# SN32F780 register map
Vendor: SONiX Technology Co., Ltd.; Series: SN32F780; File version: 0.75
CPU: CM0 r0p0, little endian, no MPU, no FPU, 2 interrupt priority bits
Registers are 32-bit, read-write, reset 0x0 unless marked. A register's access mark holds for its fields unless they carry their own. Offsets are from the block's base; [hi:lo] are bit positions; {n}, {i} and the like mark numbered series; 'fields as' and 'values as' point back to an identical list.

## SN_CT16B0 — 16-bit Timer 0 with Capture function
Base 0x40000000
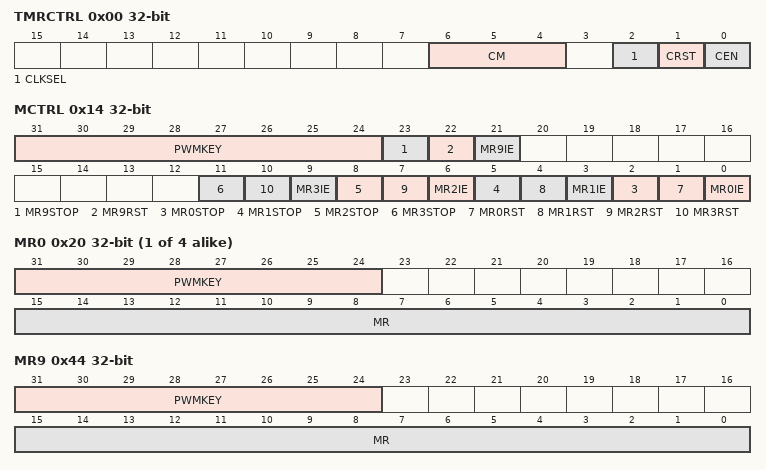
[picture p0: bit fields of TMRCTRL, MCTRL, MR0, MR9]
0x00 TMRCTRL — Offset:0x00 CT16Bn Timer Control Register
  [6:4] CM — Counting mode selection
    0=Up-counting mode (Edge-aligned Up-counting mode); 1=Down-counting mode (Edge-aligned Down-counting mode); 2=Center-aligned counting mode 1 (The match interrupt flag is set during the down-counting period); 4=Center-aligned counting mode 2 (The match interrupt flag is set during the up-counting period); 6=Center-aligned counting mode 3 (The match interrupt flag is set during both up-counting and down-counting period)
  [2] CLKSEL — PCLK source
    0=HCLK (CT16Bn PCLK source=HCLK); 1=PLL_VCO (CT16Bn PCLK source=PLL_VCO)
  [1] CRST — Counter Reset
    0=Disable Counter; 1=Reset Counter (Timer Counter and the Prescale Counter are synchronously reset on the next positive edge of PCLK)
  [0] CEN — Counter enable
    0=Disable counter; 1=Enable Timer Counter and Prescale Counter for counting
0x04 TC — Offset:0x04 CT16Bn Timer Counter Register
  [15:0] TC — Timer Counter
0x08 PRE — Offset:0x08 CT16Bn Prescale Register
  [7:0] PRE — Prescaler
0x0C PC — Offset:0x0C CT16Bn Prescale Counter Register
  [7:0] PC — Prescaler Counter
0x10 CNTCTRL — Offset:0x10 CT16Bn Counter Control Register
  [1:0] CTM — Counter/Timer Mode
    0=Timer Mode: every rising PCLK edge; 1=Counter Mode 1 (TC is incremented on rising edges on the CAP0 input selected by CIS bits.); 2=Counter Mode 2 (TC is incremented on falling edges on the CAP0 input selected by CIS bits.); 3=Counter Mode 3 (TC is incremented on both edges on the CAP0 input selected by CIS bits.)
0x14 MCTRL — Offset:0x14 CT16Bn Match Control Register
  [31:24] PWMKEY wo — PWM register key.
  [23] MR9STOP — Stop TC and PC and clear CEN bit when MR9 matches TC
    0=Disable; 1=Enable (Stop TC and PC and clear CEN bit when MR9 matches TC)
  [22] MR9RST — Enable reset TC when MR9 matches TC
    0=Disable; 1=Enable (Reset TC when MR9 matches TC)
  [21] MR9IE — Enable generating an interrupt based on CM[2:0] when MR9 matches the value in the TC
    0=Disable; 1=Enable (Generating an interrupt when MR9 matches TC)
  [3n+2] MR{n}STOP (n=0..3) — Stop TC and PC and clear CEN bit when MR{n} matches TC
    0=Disable; 1=Enable (Stop TC and PC and clear CEN bit when MR{n} matches TC)
  [3n+1] MR{n}RST (n=0..3) — Enable reset TC when MR{n} matches TC
    0=Disable; 1=Enable (Reset TC when MR{n} matches TC)
  [3n] MR{n}IE (n=0..3) — Enable generating an interrupt when MR{n} matches TC
    0=Disable; 1=Enable (Generating an interrupt when MR{n} matches TC)
{0x20+4i} MR{i} (i=0..3) — Offset:{0x20+4i} CT16Bn MR{i} Register
  [31:24] PWMKEY wo — PWM register key
  [15:0] MR — Timer counter match value
0x44 MR9 — Offset:0x44 CT16Bn MR9 Register
  fields as MR0
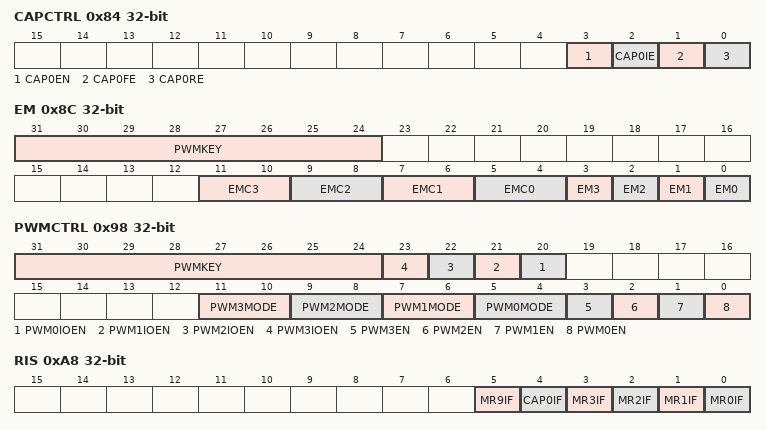
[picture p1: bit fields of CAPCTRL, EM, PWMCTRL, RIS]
0x84 CAPCTRL — Offset:0x84 CT16Bn Capture Control Register
  [3] CAP0EN — CAP0 function enable
    0=Disable; 1=Enable CAP0 function for external Capture pin
  [2] CAP0IE — Interrupt on CT16Bn_CAP0 event
    0=Disable; 1=Enable (A CAP0 load due to a CT16Bn_CAP0 event will generate an interrupt.)
  [1] CAP0FE — Capture/Reset on CT16Bn_CAP0 signal falling edge
    0=Disable; 1=Enable (A sequence of 1 then 0 on CT16Bn_CAP0 will cause CAP0 to be loaded with the contents of TC.)
  [0] CAP0RE — Capture/Reset on CT16Bn_CAP0 signal rising edge
    0=Disable; 1=Enable (A sequence of 0 then 1 on CT16Bn_CAP0 will cause CAP0 to be loaded with the contents of TC.)
0x88 CAP0 ro — Offset:0x88 CT16Bn CAP0 Register
  [15:0] CAP0 — Timer counter capture value
0x8C EM — Offset:0x8C CT16Bn External Match Register
  [31:24] PWMKEY wo — PWM register key.
  [2n+5:2n+4] EMC{n} (n=0..3) — CT16Bn_PWM{n} functionality when MR{n}=TC
    0=Do Nothing; 1=Low (CT16Bn_PWM{n} pin is LOW); 2=High (CT16Bn_PWM{n} pin is HIGH); 3=Toggle CT16Bn_PWM{n} pin
  [n] EM{n} (n=0..3) — When the TC doesn't match MR{n} and EMC{n} is not 0, this bit will drive the state of CT16Bn_PWM{n} output.
0x98 PWMCTRL — Offset:0x98 CT16Bn PWM Control Register
  [31:24] PWMKEY wo — PWM register key.
  [n+20] PWM{n}IOEN (n=0..3) — CT16Bn_PWM{n}/GPIO selection
    0=Disable (CT16Bn_PWM{n} pin is act as GPIO); 1=Enable (CT16Bn_PWM{n} pin act as match output, and output depends on PWM{n}EN bit)
  [2n+5:2n+4] PWM{n}MODE (n=0..3) — PWM{n} output mode
    0=PWM mode 1 (During up-counting, PWM{n} is 0 when TC is less than MR{n}.); 1=PWM mode 2 (During up-counting, PWM{n} is 1 when TC is less than MR{n}.); 2=Force 0 (PWM{n} is forced to 0); 3=Force 1 (PWM{n} is forced to 1)
  [3] PWM3EN — PWM2 enable
    0=Disable (CT16Bn_PWM3 is controlled by EMC3); 1=Enable PWM mode for CT16Bn_PWM3
  [2] PWM2EN — PWM2 enable
    0=Disable (CT16Bn_PWM2 is controlled by EMC2); 1=Enable PWM mode for CT16Bn_PWM2
  [1] PWM1EN — PWM1 enable
    0=Disable (CT16Bn_PWM1 is controlled by EMC1); 1=Enable PWM mode for CT16Bn_PWM1
  [0] PWM0EN — PWM0 enable
    0=Disable (CT16Bn_PWM0 is controlled by EMC0); 1=Enable PWM mode for CT16Bn_PWM0
0xA8 RIS ro — Offset:0xA8 CT16Bn Raw Interrupt Status Register
  [5] MR9IF — Match channel 9 interrupt flag
    0=No (No interrupt on match channel 9); 1=Met interrupt requirements (Interrupt requirements met on match channel 9)
  [4] CAP0IF — Capture channel 0 interrupt flag
    0=No (No interrupt on CAP0); 1=Met interrupt requirements (Interrupt requirements met on CAP0)
  [3] MR3IF — Match channel 3 interrupt flag
    0=No (No interrupt on match channel 3); 1=Met interrupt requirements (Interrupt requirements met on match channel 3)
  [2] MR2IF — Match channel 2 interrupt flag
    0=No (No interrupt on match channel 2); 1=Met interrupt requirements (Interrupt requirements met on match channel 2)
  [1] MR1IF — Match channel 1 interrupt flag
    0=No (No interrupt on match channel 1); 1=Met interrupt requirements (Interrupt requirements met on match channel 1)
  [0] MR0IF — Match channel 0 interrupt flag
    0=No interrupt on match channel 0; 1=Met interrupt requirements (Interrupt requirements met on match channel 0)
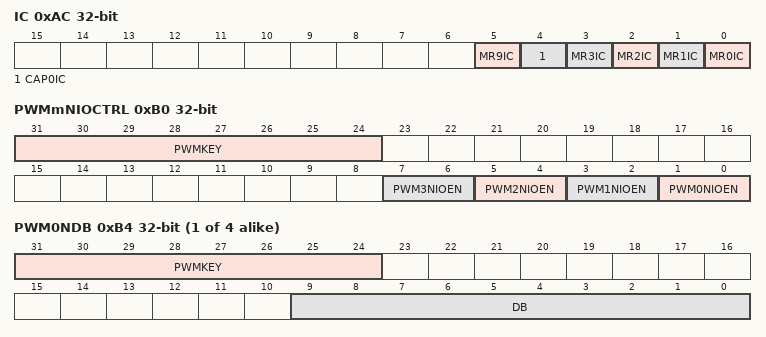
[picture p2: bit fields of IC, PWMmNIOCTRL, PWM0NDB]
0xAC IC wo — Offset:0xAC CT16Bn Interrupt Clear Register
  [5] MR9IC — MR9IF clear bit
    0=No effect; 1=Clear MR9IF
  [4] CAP0IC — CAP0IF clear bit
    0=No effect; 1=Clear CAP0IF
  [n] MR{n}IC (n=0..3) — MR{n}IF clear bit
    0=No effect; 1=Clear MR{n}IF
0xB0 PWMmNIOCTRL — Offset:0xB0 CT16Bn PWMmN IO Control register
  [31:24] PWMKEY wo — PWM register key.
  [7:6] PWM3NIOEN — CT16Bn_PWM3N/GPIO selection bit
    0=CT16Bn_PWM3N pin is act as GPIO; 1=CT16Bn_PWM3N pin outputs the inverse signal with dead-band of CT16Bn_PWM3, but same High signal during dead-band period; 2=CT16Bn_PWM3N pin outputs the inverse signal with dead-band of CT16Bn_PWM3, but same Low signal during dead-band period; 3=CT16Bn_PWM3N pin outputs the same signal with dead-band of CT16Bn_PWM3
  [5:4] PWM2NIOEN — CT16Bn_PWM0N/GPIO selection bit
    0=CT16Bn_PWM2N pin is act as GPIO; 1=CT16Bn_PWM2N pin outputs the inverse signal with dead-band of CT16Bn_PWM0, but same High signal during dead-band period; 2=CT16Bn_PWM2N pin outputs the inverse signal with dead-band of CT16Bn_PWM0, but same Low signal during dead-band period; 3=CT16Bn_PWM2N pin outputs the same signal with dead-band of CT16Bn_PWM0
  [3:2] PWM1NIOEN — CT16Bn_PWM0N/GPIO selection bit
    0=CT16Bn_PWM1N pin is act as GPIO; 1=CT16Bn_PWM1N pin outputs the inverse signal with dead-band of CT16Bn_PWM0, but same High signal during dead-band period; 2=CT16Bn_PWM1N pin outputs the inverse signal with dead-band of CT16Bn_PWM0, but same Low signal during dead-band period; 3=CT16Bn_PWM1N pin outputs the same signal with dead-band of CT16Bn_PWM0
  [1:0] PWM0NIOEN — CT16Bn_PWM0N/GPIO selection bit
    0=CT16Bn_PWM0N pin is act as GPIO; 1=CT16Bn_PWM0N pin outputs the inverse signal with dead-band of CT16Bn_PWM0, but same High signal during dead-band period; 2=CT16Bn_PWM0N pin outputs the inverse signal with dead-band of CT16Bn_PWM0, but same Low signal during dead-band period; 3=CT16Bn_PWM0N pin outputs the same signal with dead-band of CT16Bn_PWM0
{0xB4+4i} PWM{i}NDB (i=0..3) — Offset:{0xB4+4i} CT16Bn PWM{i}N Dead-band Period Register
  [31:24] PWMKEY wo — PWM register key.
  [9:0] DB — PWM{i}N output dead-band period time=DB*CT16Bn_PCLK*(PR+1) cycle
